# $root: IP-XACT component
VLNV example.org:mylibrary:$root:1.0

## Address spaces and blocks
cr_4b_mmap.cr_4b: base 'h0, range 'h11a04, width 32

## Registers
Registers are 32-bit, access per field, reset 0x3000068 unless marked. A register's access mark holds for its fields unless they carry their own. Offsets are from the block's base; lines under a group give offsets from that group; [hi:lo] are bit positions; {n}, {i} and the like mark numbered series; 'fields as' and 'values as' point back to an identical list; <NAME> marks a mode.

## cr_4b_mmap.cr_4b
Base 0x00000000
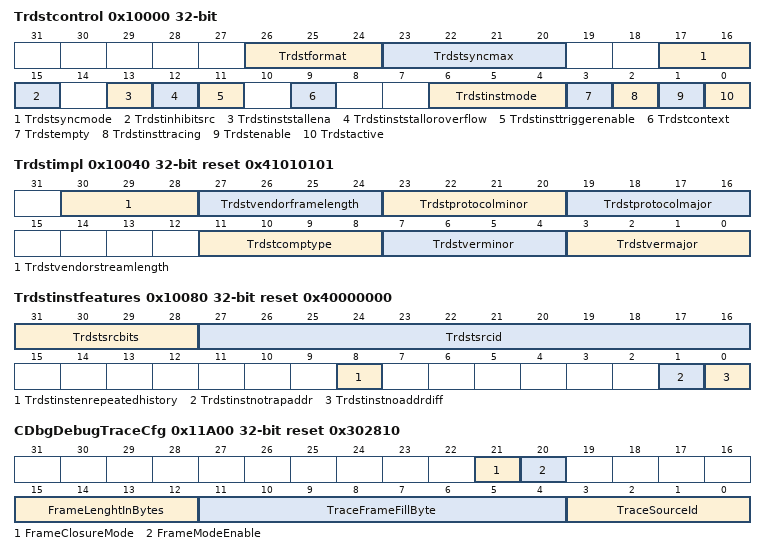
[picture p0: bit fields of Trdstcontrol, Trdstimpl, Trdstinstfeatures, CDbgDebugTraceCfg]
0x10000 Trdstcontrol
  [26:24] Trdstformat rw — bit[0]: XOR Enable, bit[1]: VLT Enable. Supported values : 2'b3 (XOR+VLT Compression), 2'b1 (XOR Compresion), 2'b0 (No Compression)
  [23:20] Trdstsyncmax rw — When trDstSyncMode is set to 2'b10, timestamp will be sent for every 2^(trDstSyncMax + 4) Cluster clocks.
  [17:16] Trdstsyncmode rw — When the field is set tp 2'b10, sent timestamp. All other vlaues not NA.
  [15] Trdstinhibitsrc ro
  [13] Trdstinststallena ro
  [12] Trdstinststalloroverflow ro
  [11] Trdstinsttriggerenable rw
  [9] Trdstcontext ro
  [6:4] Trdstinstmode ro
  [3] Trdstempty ro
  [2] Trdstinsttracing rw
  [1] Trdstenable rw
  [0] Trdstactive rw
0x10040 Trdstimpl reset 0x41010101
  [30:28] Trdstvendorstreamlength rw — Specify Stream length. A stream starts with "no compressed packet". Stream length specifies number of frames before a non-compressed packet is sent.Stream Length = 32* 2^(trDstVendorStreamLength + 1)
  [27:24] Trdstvendorframelength rw — Specify frame length. Frame Length = trDstVendorFrameLength* 64 ; Frame Length should be a multiple of Bank Data Width.
  [23:20] Trdstprotocolminor ro
  [19:16] Trdstprotocolmajor ro
  [11:8] Trdstcomptype ro
  [7:4] Trdstverminor ro
  [3:0] Trdstvermajor ro
0x10080 Trdstinstfeatures reset 0x40000000
  [31:28] Trdstsrcbits rw, [27:16] Trdstsrcid rw, [8] Trdstinstenrepeatedhistory ro, [1] Trdstinstnotrapaddr ro, [0] Trdstinstnoaddrdiff ro
0x11A00 CDbgDebugTraceCfg rw reset 0x302810
  [21] FrameClosureMode — Closure Mode: 1: Close frame with a packet no larger than max packet size before any overflow (due to packets crossing frame boundary). 0: Close frame when packets cross boundary. Push back packet crossing frame boundary to packet generator.
  [20] FrameModeEnable — Enable Frame Mode (Frame Mode: Always pack "frame length" number of bytes for trace transmission). If flush to memory is stalled (due to silicon bug), we can have incomplete packets in memory. Frame Mode will help SW decoder to avoid reading incomplete trasnmitted packets. In Frame Mode, SW will get a memory pointer that is aligned to Frame Length. HW will ensure there are no incomplete packets incluced in the region pointed by memory pointer.
  [15:12] FrameLenghtInBytes — Use trDstImpl[trDstVendorFrameLength] for Frame Length programming. Register field ZBB-ed.
  [11:4] TraceFrameFillByte — Use "Filler Packet" to align a stream of trace packets within a frame boundary.
  [3:0] TraceSourceId — Trace Source ID (FIXME: Base Address, Tool Issue)
